# ESP32 register map
Vendor: ESPRESSIF SYSTEMS (SHANGHAI) CO., LTD.; Series: ESP32 Series; File version: 17
CPU: Xtensa LX6 r0p0, little endian, no MPU, FPU, 0 interrupt priority bits
Address unit: 32 bits
Registers are 32-bit, read-write, reset 0x0 unless marked. A register's access mark holds for its fields unless they carry their own. Offsets are from the block's base; [hi:lo] are bit positions; lines under a group give offsets from that group; {n}, {i} and the like mark numbered series; 'fields as' and 'values as' point back to an identical list.

## TIMG0 — Timer Group 0
Base 0x3FF5F000
Same registers: TIMG1 0x3FF60000
{0x0+0x24*i} T{i} (i=0..1) group — Cluster T{i}, containing T?CONFIG, T?LO, T?HI, T?UPDATE, T?ALARMLO, T?ALARMHI, T?LOADLO, T?LOADHI, T?LOAD
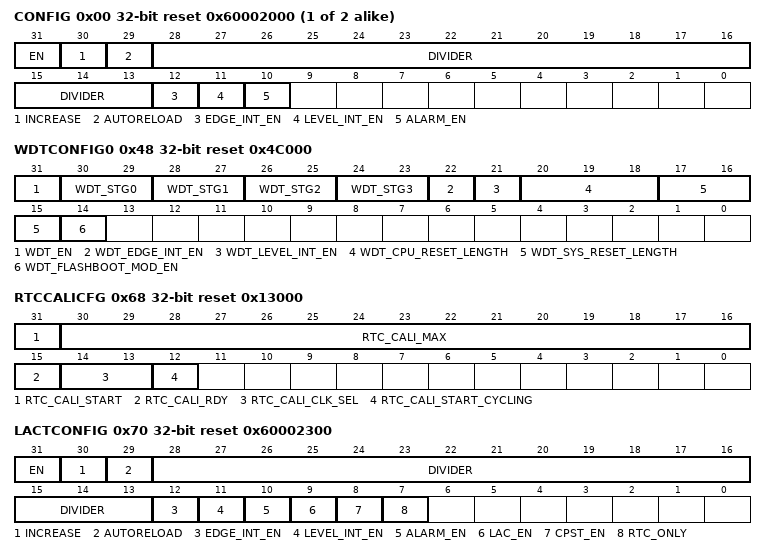
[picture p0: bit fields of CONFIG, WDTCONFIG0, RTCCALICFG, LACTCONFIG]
  0x00 CONFIG reset 0x60002000
    [31] EN — When set timer 0 time-base counter is enabled
    [30] INCREASE — When set timer 0 time-base counter increment. When cleared timer 0 time-base counter decrement.
    [29] AUTORELOAD — When set timer 0 auto-reload at alarming is enabled
    [28:13] DIVIDER — Timer 0 clock (T0_clk) prescale value.
    [12] EDGE_INT_EN — When set edge type interrupt will be generated during alarm
    [11] LEVEL_INT_EN — When set level type interrupt will be generated during alarm
    [10] ALARM_EN — When set alarm is enabled
  0x04 LO ro
    [31:0] LO — Register to store timer 0 time-base counter current value lower 32 bits.
  0x08 HI ro
    [31:0] HI — Register to store timer 0 time-base counter current value higher 32 bits.
  0x0C UPDATE
    [31] UPDATE — Write any value will trigger a timer 0 time-base counter value update (timer 0 current value will be stored in registers above)
  0x10 ALARMLO
    [31:0] ALARM_LO — Timer 0 time-base counter value lower 32 bits that will trigger the alarm
  0x14 ALARMHI
    [31:0] ALARM_HI — Timer 0 time-base counter value higher 32 bits that will trigger the alarm
  0x18 LOADLO
    [31:0] LOAD_LO — Lower 32 bits of the value that will load into timer 0 time-base counter
  0x1C LOADHI
    [31:0] LOAD_HI — higher 32 bits of the value that will load into timer 0 time-base counter
  0x20 LOAD wo
    [31:0] LOAD — Write any value will trigger timer 0 time-base counter reload
0x48 WDTCONFIG0 reset 0x4C000
  [31] WDT_EN — When set SWDT is enabled
  [30-2n:29-2n] WDT_STG{n} (n=0..3) — Stage {n} configuration. 0: off 1: interrupt 2: reset CPU 3: reset system
    0=OFF; 1=INTERRUPT; 2=RESET (Reset CPU); 3=RESET_SYS (Reset system)
  [22] WDT_EDGE_INT_EN — When set edge type interrupt generation is enabled
  [21] WDT_LEVEL_INT_EN — When set level type interrupt generation is enabled
  [20:18] WDT_CPU_RESET_LENGTH — length of CPU reset selection. 0: 100ns 1: 200ns 2: 300ns 3: 400ns 4: 500ns 5: 800ns 6: 1.6us 7: 3.2us
    0=NS100 (100ns); 1=NS200 (200ns); 2=NS300 (300ns); 3=NS400 (400ns); 4=NS500 (500ns); 5=NS800 (800ns); 6=NS1600 (1.6us); 7=NS3200 (3.2us)
  [17:15] WDT_SYS_RESET_LENGTH — length of system reset selection. 0: 100ns 1: 200ns 2: 300ns 3: 400ns 4: 500ns 5: 800ns 6: 1.6us 7: 3.2us
    values as WDT_CPU_RESET_LENGTH
  [14] WDT_FLASHBOOT_MOD_EN — When set flash boot protection is enabled
0x4C WDTCONFIG1 reset 0x10000
  [31:16] WDT_CLK_PRESCALE — SWDT clock prescale value. Period = 12.5ns * value stored in this register
{0x48+4i} WDTCONFIG{i} (i=2..5) reset 0x18CBA80 — Watchdog timer stage timeout value
  [31:0] HOLD — Stage 0 timeout value in SWDT clock cycles
0x60 WDTFEED wo
  [31:0] WDT_FEED — Write any value will feed SWDT
0x64 WDTWPROTECT reset 0x50D83AA1
  [31:0] WDT_WKEY — If change its value from default then write protection is on.
0x68 RTCCALICFG access per field reset 0x13000
  [31] RTC_CALI_START rw, [30:16] RTC_CALI_MAX rw, [15] RTC_CALI_RDY ro, [14:13] RTC_CALI_CLK_SEL rw, [12] RTC_CALI_START_CYCLING rw
0x6C RTCCALICFG1 ro
  [31:7] RTC_CALI_VALUE
0x70 LACTCONFIG reset 0x60002300
  [31] EN, [30] INCREASE, [29] AUTORELOAD, [28:13] DIVIDER, [12] EDGE_INT_EN, [11] LEVEL_INT_EN, [10] ALARM_EN, [9] LAC_EN, [8] CPST_EN, [7] RTC_ONLY
0x74 LACTRTC
  [31:6] RTC_STEP_LEN
0x78 LACTLO ro
  [31:0] LO
0x7C LACTHI ro
  [31:0] HI
0x80 LACTUPDATE wo
  [31:0] UPDATE
0x84 LACTALARMLO
  [31:0] ALARM_LO
0x88 LACTALARMHI
  [31:0] ALARM_HI
0x8C LACTLOADLO
  [31:0] LOAD_LO
0x90 LACTLOADHI
  [31:0] LOAD_HI
0x94 LACTLOAD wo
  [31:0] LOAD
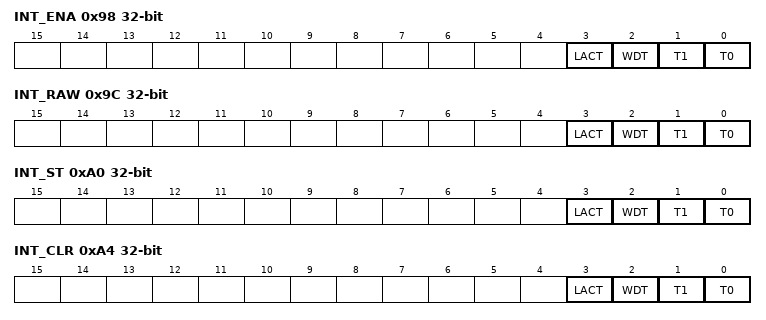
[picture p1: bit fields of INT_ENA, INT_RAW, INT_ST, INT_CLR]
0x98 INT_ENA
  [3] LACT
  [2] WDT — Interrupt when an interrupt stage timeout
  [n] T{n} (n=0..1) — interrupt when timer{n} alarm
0x9C INT_RAW ro
  fields as INT_ENA
0xA0 INT_ST ro
  fields as INT_ENA
0xA4 INT_CLR wo
  [3] LACT write-1-clears
  [2] WDT write-1-clears — Interrupt when an interrupt stage timeout
  [n] T{n} (n=0..1) write-1-clears — interrupt when timer{n} alarm
0xF8 NTIMERS_DATE
0xFC TIMGCLK
  [31] CLK_EN — Force clock enable for this regfile
